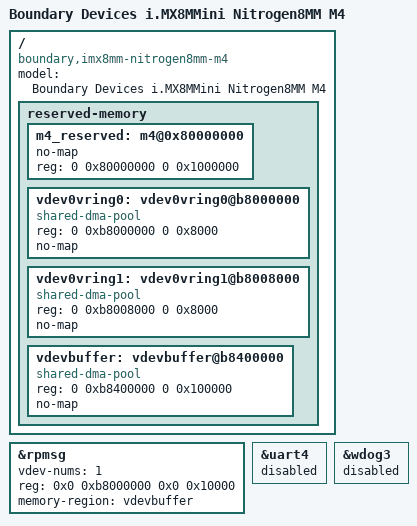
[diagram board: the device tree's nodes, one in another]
// SPDX-License-Identifier: (GPL-2.0+ OR MIT)
/*
 * Copyright 2018 Boundary Devices
 */

#include "imx8mm-nitrogen8mm.dts"

/ {
	model = "Boundary Devices i.MX8MMini Nitrogen8MM M4";
	compatible = "boundary,imx8mm-nitrogen8mm-m4", "fsl,imx8mm";

	reserved-memory {
		#address-cells = <2>;
		#size-cells = <2>;
		ranges;

		m4_reserved: m4@0x80000000 {
			no-map;
			reg = <0 0x80000000 0 0x1000000>;
		};

		vdev0vring0: vdev0vring0@b8000000 {
			compatible = "shared-dma-pool";
			reg = <0 0xb8000000 0 0x8000>;
			no-map;
		};

		vdev0vring1: vdev0vring1@b8008000 {
			compatible = "shared-dma-pool";
			reg = <0 0xb8008000 0 0x8000>;
			no-map;
		};

		vdevbuffer: vdevbuffer@b8400000 {
			compatible = "shared-dma-pool";
			reg = <0 0xb8400000 0 0x100000>;
			no-map;
		};
	};
};

&rpmsg{
	/*
	 * 64K for one rpmsg instance:
	 * --0xb8000000~0xb800ffff: pingpong
	 */
	vdev-nums = <1>;
	reg = <0x0 0xb8000000 0x0 0x10000>;
	memory-region = <&vdevbuffer>;
	status = "okay";
};

&uart4 {
	status = "disabled";
};

&wdog3{
	status = "disabled";
};
